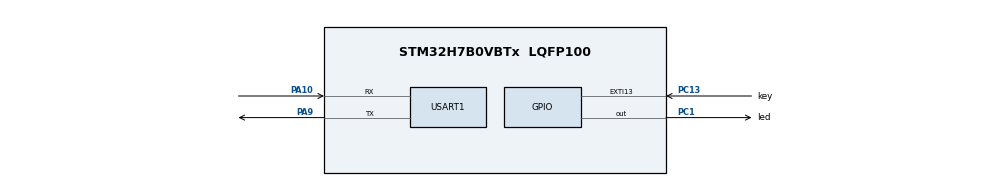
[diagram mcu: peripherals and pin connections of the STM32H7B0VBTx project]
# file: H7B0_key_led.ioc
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Mcu.Family=STM32H7
Mcu.Name=STM32H7B0VBTx
Mcu.Package=LQFP100
NVIC.EXTI15_10_IRQn=true\:1\:1\:true\:false\:true\:true\:true
NVIC.PriorityGroup=NVIC_PRIORITYGROUP_2
NVIC.USART1_IRQn=true\:1\:0\:true\:false\:true\:true\:true
PA10.Mode=Asynchronous
PA10.Signal=USART1_RX
PA13.Mode=Serial_Wire
PA13.Signal=DEBUG_JTMS-SWDIO
PA14.Mode=Serial_Wire
PA14.Signal=DEBUG_JTCK-SWCLK
PA9.Mode=Asynchronous
PA9.Signal=USART1_TX
PC1.GPIO_Label=led
PC1.GPIO_Speed=GPIO_SPEED_FREQ_HIGH
PC1.Signal=GPIO_Output
PC13.GPIO_Label=key
PC13.GPIO_ModeDefaultEXTI=GPIO_MODE_IT_FALLING
PC13.GPIO_PuPd=GPIO_PULLUP
PC13.Signal=GPXTI13
PH0-OSC_IN.Mode=HSE-External-Oscillator
PH0-OSC_IN.Signal=RCC_OSC_IN
PH1-OSC_OUT.Mode=HSE-External-Oscillator
PH1-OSC_OUT.Signal=RCC_OSC_OUT
ProjectManager.HeapSize=0x200
ProjectManager.StackSize=0x400
ProjectManager.TargetToolchain=MDK-ARM V5.27
RCC.ADCFreq_Value=129000000
RCC.APB1Freq_Value=140000000
RCC.APB2Freq_Value=140000000
RCC.APB3Freq_Value=140000000
RCC.APB4Freq_Value=140000000
RCC.CDPPRE=RCC_APB3_DIV2
RCC.CDPPRE1=RCC_APB1_DIV2
RCC.CDPPRE2=RCC_APB2_DIV2
RCC.CortexFreq_Value=280000000
RCC.DIVM1=4
RCC.DIVN1=35
RCC.HCLKFreq_Value=280000000
RCC.HSE_VALUE=25000000
RCC.PLL2FRACN=0
RCC.PLL3FRACN=0
RCC.PLLFRACN=0
RCC.SRDPPRE=RCC_APB4_DIV2
RCC.SYSCLKFreq_VALUE=280000000
RCC.SYSCLKSource=RCC_SYSCLKSOURCE_PLLCLK
RCC.USBFreq_Value=280000000
USART1.VirtualMode-Asynchronous=VM_ASYNC
board=custom

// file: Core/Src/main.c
/* USER CODE BEGIN Header */
/**
 ******************************************************************************
 * @file           : main.c
 * @brief          : Main program body
 ******************************************************************************
 * @attention
 *
 * <h2><center>&copy; Copyright (c) 2023 STMicroelectronics.
 * All rights reserved.</center></h2>
 *
 * This software component is licensed by ST under BSD 3-Clause license,
 * the "License"; You may not use this file except in compliance with the
 * License. You may obtain a copy of the License at:
 *                        opensource.org/licenses/BSD-3-Clause
 *
 ******************************************************************************
 */
/* USER CODE END Header */
#include "main.h"

UART_HandleTypeDef huart1;

void SystemClock_Config(void);
static void MX_GPIO_Init(void);
static void MX_USART1_UART_Init(void);

/* USER CODE BEGIN 0 */
int fputc(int ch, FILE *f)
{
  /* 发送一个字节数据到串口 USARTx */
  HAL_UART_Transmit(&huart1, (uint8_t *)&ch, 1, 0xFF);
  return (ch);
}
void Usart_SendString(uint8_t *str)
{
  unsigned int k = 0;
  do
  {
    HAL_UART_Transmit(&huart1, (uint8_t *)(str + k), 1, 1000);
    k++;
  } while (*(str + k) != '\0');
}

/* USER CODE END 0 */

int main(void)
{
  /* USER CODE BEGIN 1 */
  char *date = "biubiu";
  /* USER CODE END 1 */

  /* MCU Configuration--------------------------------------------------------*/

  /* Reset of all peripherals, Initializes the Flash interface and the Systick. */
  HAL_Init();

  /* Configure the system clock */
  SystemClock_Config();

  /* Initialize all configured peripherals */
  MX_GPIO_Init();
  MX_USART1_UART_Init();

  /* Infinite loop */
  /* USER CODE BEGIN WHILE */
  while (1)
  {
    HAL_UART_Transmit(&huart1, (uint8_t *)date, 7, 1000);
    HAL_Delay(1000);
    printf("你是傻子\n");

    /* USER CODE END WHILE */

  }
}

void SystemClock_Config(void)
{
  RCC_OscInitTypeDef RCC_OscInitStruct = {0};
  RCC_ClkInitTypeDef RCC_ClkInitStruct = {0};
  RCC_PeriphCLKInitTypeDef PeriphClkInitStruct = {0};

  /** Supply configuration update enable
   */
  HAL_PWREx_ConfigSupply(PWR_LDO_SUPPLY);
  /** Configure the main internal regulator output voltage
   */
  __HAL_PWR_VOLTAGESCALING_CONFIG(PWR_REGULATOR_VOLTAGE_SCALE0);

  while (!__HAL_PWR_GET_FLAG(PWR_FLAG_VOSRDY))
  {
  }
  /** Initializes the RCC Oscillators according to the specified parameters
   * in the RCC_OscInitTypeDef structure.
   */
  RCC_OscInitStruct.OscillatorType = RCC_OSCILLATORTYPE_HSI;
  RCC_OscInitStruct.HSIState = RCC_HSI_DIV1;
  RCC_OscInitStruct.HSICalibrationValue = RCC_HSICALIBRATION_DEFAULT;
  RCC_OscInitStruct.PLL.PLLState = RCC_PLL_ON;
  RCC_OscInitStruct.PLL.PLLSource = RCC_PLLSOURCE_HSI;
  RCC_OscInitStruct.PLL.PLLM = 4;
  RCC_OscInitStruct.PLL.PLLN = 35;
  RCC_OscInitStruct.PLL.PLLP = 2;
  RCC_OscInitStruct.PLL.PLLQ = 2;
  RCC_OscInitStruct.PLL.PLLR = 2;
  RCC_OscInitStruct.PLL.PLLRGE = RCC_PLL1VCIRANGE_3;
  RCC_OscInitStruct.PLL.PLLVCOSEL = RCC_PLL1VCOWIDE;
  RCC_OscInitStruct.PLL.PLLFRACN = 0;
  if (HAL_RCC_OscConfig(&RCC_OscInitStruct) != HAL_OK)
  {
    Error_Handler();
  }
  /** Initializes the CPU, AHB and APB buses clocks
   */
  RCC_ClkInitStruct.ClockType = RCC_CLOCKTYPE_HCLK | RCC_CLOCKTYPE_SYSCLK | RCC_CLOCKTYPE_PCLK1 | RCC_CLOCKTYPE_PCLK2 | RCC_CLOCKTYPE_D3PCLK1 | RCC_CLOCKTYPE_D1PCLK1;
  RCC_ClkInitStruct.SYSCLKSource = RCC_SYSCLKSOURCE_PLLCLK;
  RCC_ClkInitStruct.SYSCLKDivider = RCC_SYSCLK_DIV1;
  RCC_ClkInitStruct.AHBCLKDivider = RCC_HCLK_DIV1;
  RCC_ClkInitStruct.APB3CLKDivider = RCC_APB3_DIV2;
  RCC_ClkInitStruct.APB1CLKDivider = RCC_APB1_DIV2;
  RCC_ClkInitStruct.APB2CLKDivider = RCC_APB2_DIV2;
  RCC_ClkInitStruct.APB4CLKDivider = RCC_APB4_DIV2;

  if (HAL_RCC_ClockConfig(&RCC_ClkInitStruct, FLASH_LATENCY_7) != HAL_OK)
  {
    Error_Handler();
  }
  PeriphClkInitStruct.PeriphClockSelection = RCC_PERIPHCLK_USART16;
  PeriphClkInitStruct.Usart16ClockSelection = RCC_USART16910CLKSOURCE_D2PCLK2;
  if (HAL_RCCEx_PeriphCLKConfig(&PeriphClkInitStruct) != HAL_OK)
  {
    Error_Handler();
  }
}

static void MX_USART1_UART_Init(void)
{

  huart1.Instance = USART1;
  huart1.Init.BaudRate = 115200;
  huart1.Init.WordLength = UART_WORDLENGTH_8B;
  huart1.Init.StopBits = UART_STOPBITS_1;
  huart1.Init.Parity = UART_PARITY_NONE;
  huart1.Init.Mode = UART_MODE_TX_RX;
  huart1.Init.HwFlowCtl = UART_HWCONTROL_NONE;
  huart1.Init.OverSampling = UART_OVERSAMPLING_16;
  huart1.Init.OneBitSampling = UART_ONE_BIT_SAMPLE_DISABLE;
  huart1.Init.ClockPrescaler = UART_PRESCALER_DIV1;
  huart1.AdvancedInit.AdvFeatureInit = UART_ADVFEATURE_NO_INIT;
  if (HAL_UART_Init(&huart1) != HAL_OK)
  {
    Error_Handler();
  }
  if (HAL_UARTEx_SetTxFifoThreshold(&huart1, UART_TXFIFO_THRESHOLD_1_8) != HAL_OK)
  {
    Error_Handler();
  }
  if (HAL_UARTEx_SetRxFifoThreshold(&huart1, UART_RXFIFO_THRESHOLD_1_8) != HAL_OK)
  {
    Error_Handler();
  }
  if (HAL_UARTEx_DisableFifoMode(&huart1) != HAL_OK)
  {
    Error_Handler();
  }
}

static void MX_GPIO_Init(void)
{
  GPIO_InitTypeDef GPIO_InitStruct = {0};

  /* GPIO Ports Clock Enable */
  __HAL_RCC_GPIOC_CLK_ENABLE();
  __HAL_RCC_GPIOH_CLK_ENABLE();
  __HAL_RCC_GPIOA_CLK_ENABLE();

  /*Configure GPIO pin Output Level */
  HAL_GPIO_WritePin(led_GPIO_Port, led_Pin, GPIO_PIN_RESET);

  /*Configure GPIO pin : key_Pin */
  GPIO_InitStruct.Pin = key_Pin;
  GPIO_InitStruct.Mode = GPIO_MODE_IT_FALLING;
  GPIO_InitStruct.Pull = GPIO_PULLUP;
  HAL_GPIO_Init(key_GPIO_Port, &GPIO_InitStruct);

  /*Configure GPIO pin : led_Pin */
  GPIO_InitStruct.Pin = led_Pin;
  GPIO_InitStruct.Mode = GPIO_MODE_OUTPUT_PP;
  GPIO_InitStruct.Pull = GPIO_NOPULL;
  GPIO_InitStruct.Speed = GPIO_SPEED_FREQ_HIGH;
  HAL_GPIO_Init(led_GPIO_Port, &GPIO_InitStruct);

  /* EXTI interrupt init*/
  HAL_NVIC_SetPriority(EXTI15_10_IRQn, 1, 1);
  HAL_NVIC_EnableIRQ(EXTI15_10_IRQn);
}

void Error_Handler(void)
{
  __disable_irq();
  while (1)
  {
  }
}

/************************ (C) COPYRIGHT STMicroelectronics *****END OF FILE****/
